# Montana register map
Vendor: ONSemiconductor; Series: Montana Series; File version: 1.0
CPU: CM33 r0p4, little endian, MPU, FPU, 3 interrupt priority bits
Registers are 32-bit, read-write, reset 0x0 unless marked. A register's access mark holds for its fields unless they carry their own. Offsets are from the block's base; [hi:lo] are bit positions; 'fields as' and 'values as' point back to an identical list.

## SYSCTRL — System Control
Base 0x40000000
0x00 SYSCTRL_CM33_LOOP_CACHE_CFG — CM33 Loop Cache Configuration
  [0] CM33_LOOP_CACHE_ENABLE
    0=CM33_LOOP_CACHE_DISABLE (CM33 loop cache disabled); 1=CM33_LOOP_CACHE_ENABLE (CM33 loop cache enabled)
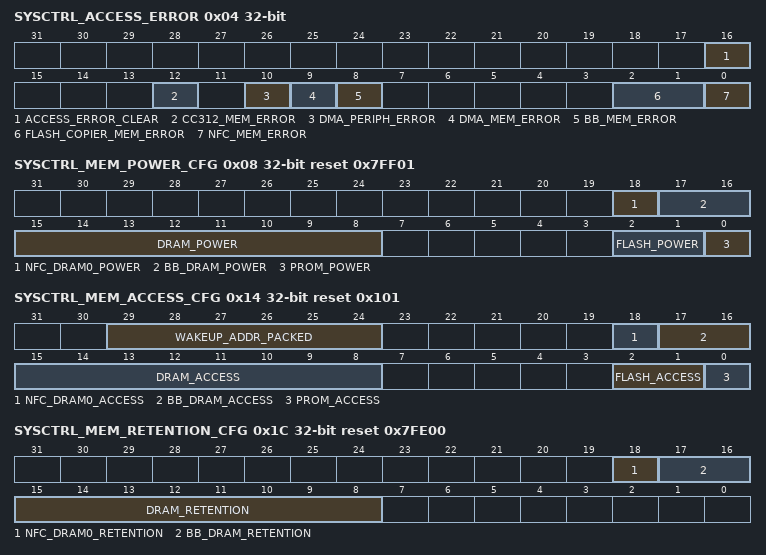
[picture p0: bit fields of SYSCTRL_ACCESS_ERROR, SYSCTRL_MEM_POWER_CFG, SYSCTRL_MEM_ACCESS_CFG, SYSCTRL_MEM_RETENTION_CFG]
0x04 SYSCTRL_ACCESS_ERROR (reset mask 0x1707) — Memory and Peripheral Access Error Flags
  [16] ACCESS_ERROR_CLEAR wo — Write a 1 to clear the access error flags
    1=SYSCTRL_ACCESS_ERROR_CLEAR (Clear the access error flags)
  [12] CC312_MEM_ERROR ro — CC312 memory error flag
    0=CC312_MEM_NO_ERROR_DETECTED (No CC312 memory error detected); 1=CC312_MEM_ERROR_DETECTED (CC312 has accessed an isolated memory)
  [10] DMA_PERIPH_ERROR ro — DMA peripheral access error flag
    0=DMA_PERIPH_NO_ERROR_DETECTED (No DMA peripheral access error detected); 1=DMA_PERIPH_ERROR_DETECTED (DMA received a peripheral access error)
  [9] DMA_MEM_ERROR ro — DMA memory error flag
    0=DMA_MEM_NO_ERROR_DETECTED (No DMA memory error detected); 1=DMA_MEM_ERROR_DETECTED (DMA has accessed an isolated memory)
  [8] BB_MEM_ERROR ro — Baseband memory error flag
    0=BB_MEM_NO_ERROR_DETECTED (No baseband memory error detected); 1=BB_MEM_ERROR_DETECTED (Baseband has accessed an isolated memory)
  [2:1] FLASH_COPIER_MEM_ERROR ro — FLASH[1:0] copier memory error flag
    0=FLASH0_COPIER_MEM_NO_ERROR_DETECTED (No FLASH copier memory error detected); 0=FLASH1_COPIER_MEM_NO_ERROR_DETECTED (No FLASH copier memory error detected); 1=FLASH0_COPIER_MEM_ERROR_DETECTED (FLASH0 or FLASH1 copier have accessed an isolated memory); 2=FLASH1_COPIER_MEM_ERROR_DETECTED (FLASH0 or FLASH1 copier have accessed an isolated memory)
  [0] NFC_MEM_ERROR ro — NFC controller memory error flag
    0=NFC_MEM_NO_ERROR_DETECTED (No NFC controller memory error detected); 1=NFC_MEM_ERROR_DETECTED (NFC controller memory error detected)
0x08 SYSCTRL_MEM_POWER_CFG reset 0x7FF01 — Memory Power Configuration
  [18] NFC_DRAM0_POWER — NFC DRAM0 power configuration
    0=NFC_DRAM0_POWER_DISABLE (NFC DRAM0 power disabled); 1=NFC_DRAM0_POWER_ENABLE (NFC DRAM0 power enabled)
  [17:16] BB_DRAM_POWER — Baseband DRAM[1:0] power configuration (one bit per RAM instance)
    0=BB_DRAM0_POWER_DISABLE (Baseband DRAM0 power disabled); 0=BB_DRAM1_POWER_DISABLE (Baseband DRAM1 power disabled); 1=BB_DRAM0_POWER_ENABLE (Baseband DRAM0 power enabled); 2=BB_DRAM1_POWER_ENABLE (Baseband DRAM1 power enabled)
  [15:8] DRAM_POWER — DRAM[7:0] power configuration (one bit per RAM instance)
    0=DRAM0_POWER_DISABLE (DRAM0 power disabled); 0=DRAM1_POWER_DISABLE (DRAM1 power disabled); 0=DRAM2_POWER_DISABLE (DRAM2 power disabled); 0=DRAM3_POWER_DISABLE (DRAM3 power disabled); 0=DRAM4_POWER_DISABLE (DRAM4 power disabled); 0=DRAM5_POWER_DISABLE (DRAM5 power disabled); 0=DRAM6_POWER_DISABLE (DRAM6 power disabled); 0=DRAM7_POWER_DISABLE (DRAM7 power disabled); 1=DRAM0_POWER_ENABLE (DRAM0 power enabled); 2=DRAM1_POWER_ENABLE (DRAM1 power enabled); 4=DRAM2_POWER_ENABLE (DRAM2 power enabled); 8=DRAM3_POWER_ENABLE (DRAM3 power enabled); 16=DRAM4_POWER_ENABLE (DRAM4 power enabled); 32=DRAM5_POWER_ENABLE (DRAM5 power enabled); 64=DRAM6_POWER_ENABLE (DRAM6 power enabled); 128=DRAM7_POWER_ENABLE (DRAM7 power enabled)
  [2:1] FLASH_POWER — Flash[1:0] power configuration (one bit per FLASH instance)
    0=FLASH0_POWER_DISABLE (FLASH0 power disabled); 0=FLASH1_POWER_DISABLE (FLASH1 power disabled); 1=FLASH0_POWER_ENABLE (FLASH0 power enabled); 2=FLASH1_POWER_ENABLE (FLASH1 power enabled)
  [0] PROM_POWER — PROM power configuration
    0=PROM_POWER_DISABLE (PROM power disabled); 1=PROM_POWER_ENABLE (PROM power enabled)
0x14 SYSCTRL_MEM_ACCESS_CFG reset 0x101 — Memory Access Configuration and Wakeup Restore Address in packed 4-bit format
  [29:24] WAKEUP_ADDR_PACKED — Wakeup restore address in packed 6-bit format. When written, SYSCTRL_WAKEUP_ADDR is updated. This field reads back as zero when SYSCTRL_WAKEUP_ADDR does not point to an enabled RAM instance.
  [18] NFC_DRAM0_ACCESS — NFC DRAM0 access configuration
    0=NFC_DRAM0_ACCESS_DISABLE (NFC DRAM0 access disabled); 1=NFC_DRAM0_ACCESS_ENABLE (NFC RAM0 access enabled)
  [17:16] BB_DRAM_ACCESS — Baseband DRAM[1:0] access configuration
    0=BB_DRAM0_ACCESS_DISABLE (Baseband DRAM0 access disabled); 0=BB_DRAM1_ACCESS_DISABLE (Baseband DRAM1 access disabled); 1=BB_DRAM0_ACCESS_ENABLE (Baseband DRAM0 access enabled); 2=BB_DRAM1_ACCESS_ENABLE (Baseband DRAM1 access enabled)
  [15:8] DRAM_ACCESS — DRAM[7:0] access configuration
    0=DRAM0_ACCESS_DISABLE (DRAM0 access disabled); 0=DRAM1_ACCESS_DISABLE (DRAM1 access disabled); 0=DRAM2_ACCESS_DISABLE (DRAM2 access disabled); 0=DRAM3_ACCESS_DISABLE (DRAM3 access disabled); 0=DRAM4_ACCESS_DISABLE (DRAM4 access disabled); 0=DRAM5_ACCESS_DISABLE (DRAM5 access disabled); 0=DRAM6_ACCESS_DISABLE (DRAM6 access disabled); 0=DRAM7_ACCESS_DISABLE (DRAM7 access disabled); 1=DRAM0_ACCESS_ENABLE (DRAM0 access enabled); 2=DRAM1_ACCESS_ENABLE (DRAM1 access enabled); 4=DRAM2_ACCESS_ENABLE (DRAM2 access enabled); 8=DRAM3_ACCESS_ENABLE (DRAM3 access enabled); 16=DRAM4_ACCESS_ENABLE (DRAM4 access enabled); 32=DRAM5_ACCESS_ENABLE (DRAM5 access enabled); 64=DRAM6_ACCESS_ENABLE (DRAM6 access enabled); 128=DRAM7_ACCESS_ENABLE (DRAM7 access enabled)
  [2:1] FLASH_ACCESS — FLASH[1:0] access configuration
    0=FLASH0_ACCESS_DISABLE (FLASH0 access disabled); 0=FLASH1_ACCESS_DISABLE (FLASH1 access disabled); 1=FLASH0_ACCESS_ENABLE (FLASH0 access enabled); 2=FLASH1_ACCESS_ENABLE (FLASH1 access enabled)
  [0] PROM_ACCESS — PROM access configuration
    0=PROM_ACCESS_DISABLE (PROM access disabled); 1=PROM_ACCESS_ENABLE (PROM access enabled)
0x18 SYSCTRL_WAKEUP_ADDR — Wakeup Restore Address in Unpacked 32-bit Format
  [31:0] WAKEUP_ADDR — Wakeup restore address in unpacked 32-bit format.
0x1C SYSCTRL_MEM_RETENTION_CFG reset 0x7FE00 — Memory Retention Configuration
  [18] NFC_DRAM0_RETENTION — NFC DRAM0 retention configuration
    0=NFC_DRAM0_NORMAL_MODE; 1=NFC_DRAM0_RETENTION_MODE
  [17:16] BB_DRAM_RETENTION — Baseband DRAM[1:0] retention configuration
    0=BB_DRAM0_NORMAL_MODE (Baseband DRAM0 normal mode); 0=BB_DRAM1_NORMAL_MODE (Baseband DRAM1 normal mode); 1=BB_DRAM0_RETENTION_MODE (Baseband DRAM0 retention mode); 2=BB_DRAM1_RETENTION_MODE (Baseband DRAM1 retention mode)
  [15:8] DRAM_RETENTION — DRAM[7:0] retention configuration
    0=DRAM0_NORMAL_MODE; 0=DRAM1_NORMAL_MODE; 0=DRAM2_NORMAL_MODE; 0=DRAM3_NORMAL_MODE; 0=DRAM4_NORMAL_MODE; 0=DRAM5_NORMAL_MODE; 0=DRAM6_NORMAL_MODE; 0=DRAM7_NORMAL_MODE; 1=DRAM0_RETENTION_MODE; 2=DRAM1_RETENTION_MODE; 4=DRAM2_RETENTION_MODE; 8=DRAM3_RETENTION_MODE; 16=DRAM4_RETENTION_MODE; 32=DRAM5_RETENTION_MODE; 64=DRAM6_RETENTION_MODE; 128=DRAM7_RETENTION_MODE
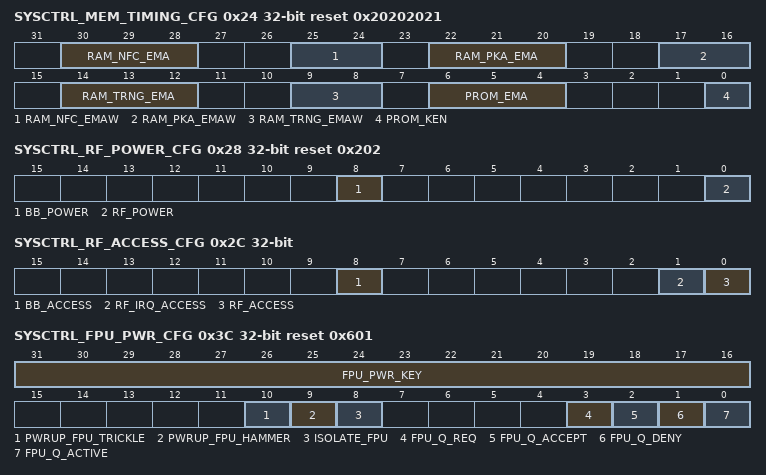
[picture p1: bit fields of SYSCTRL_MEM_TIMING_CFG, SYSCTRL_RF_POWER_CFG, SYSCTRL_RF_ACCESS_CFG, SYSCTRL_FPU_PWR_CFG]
0x24 SYSCTRL_MEM_TIMING_CFG reset 0x20202021 — Memory Timing Configuration
  [30:28] RAM_NFC_EMA — RAM extra margin configuration for NFC RAM
    0=RAM_NFC_EMA_MIN (RAM minimum extra margin); 2=RAM_NFC_EMA_DEFAULT (RAM default extra margin); 7=RAM_NFC_EMA_MAX (RAM maximum extra margin)
  [25:24] RAM_NFC_EMAW — RAM write extra margin configuration for NFC RAM
    0=RAM_NFC_EMAW_DEFAULT (RAM default/minimum extra write margin); 3=RAM_NFC_EMAW_MAX (RAM maximum extra write margin)
  [22:20] RAM_PKA_EMA — RAM extra margin configuration for PKA RAM
    0=RAM_PKA_EMA_MIN (RAM minimum extra margin); 2=RAM_PKA_EMA_DEFAULT (RAM default extra margin); 7=RAM_PKA_EMA_MAX (RAM maximum extra margin)
  [17:16] RAM_PKA_EMAW — RAM write extra margin configuration for PKA RAM
    0=RAM_PKA_EMAW_DEFAULT (RAM default/minimum extra write margin); 3=RAM_PKA_EMAW_MAX (RAM maximum extra write margin)
  [14:12] RAM_TRNG_EMA — RAM extra margin configuration for TRNG RAM
    0=RAM_TRNG_EMA_MIN (RAM minimum extra margin); 2=RAM_TRNG_EMA_DEFAULT (RAM default extra margin); 7=RAM_TRNG_EMA_MAX (RAM maximum extra margin)
  [9:8] RAM_TRNG_EMAW — RAM write extra margin configuration for TRNG RAM
    0=RAM_TRNG_EMAW_DEFAULT (RAM default/minimum extra write margin); 3=RAM_TRNG_EMAW_MAX (RAM maximum extra write margin)
  [6:4] PROM_EMA — PROM extra margin configuration
    0=PROM_EMA_MIN (PROM minimum extra margin); 2=PROM_EMA_DEFAULT (PROM default extra margin); 7=PROM_EMA_MAX (PROM maximum extra margin)
  [0] PROM_KEN — PROM bit lines keeper configuration
    0=PROM_KEN_ENABLED (PROM bit lines keeper enabled); 1=PROM_KEN_DISABLED (PROM bit lines keeper disabled)
0x28 SYSCTRL_RF_POWER_CFG reset 0x202 — RF Power Configuration
  [8] BB_POWER — Base Band power configuration
    0=BB_POWER_DISABLE (Base Band power disabled); 1=BB_POWER_ENABLE (Base Band power enabled)
  [0] RF_POWER — RF power configuration
    0=RF_POWER_DISABLE (RF power disabled); 1=RF_POWER_ENABLE (RF power enabled)
0x2C SYSCTRL_RF_ACCESS_CFG — RF Access Configuration
  [8] BB_ACCESS — Base Band access
    0=BB_ACCESS_DISABLE (BB access disabled); 1=BB_ACCESS_ENABLE (BB access enabled)
  [1] RF_IRQ_ACCESS — RF IRQ access configuration
    0=RF_IRQ_ACCESS_DISABLE (RF IRQ access disabled); 1=RF_IRQ_ACCESS_ENABLE (RF IRQ access enabled)
  [0] RF_ACCESS — RF access configuration
    0=RF_ACCESS_DISABLE (RF access disabled); 1=RF_ACCESS_ENABLE (RF access enabled)
0x34 SYSCTRL_WAKEUP_PAD ro — WAKEUP Pad Value
  [0] WAKEUP_PAD_VALUE
    0=WAKEUP_PAD_LOW (WAKEUP pad value equal to '0'); 1=WAKEUP_PAD_HIGH (WAKEUP pad value equal to '1')
0x3C SYSCTRL_FPU_PWR_CFG reset 0x601 (reset mask 0x170F) — FPU Power Configuration
  [31:16] FPU_PWR_KEY wo — Key to enable write to this register
    0x4644=FPU_WRITE_KEY (Key to enable write to this register)
  [10] PWRUP_FPU_TRICKLE — Power control for FPU primary current in-rush limited supply
    0=FPU_PWR_TRICKLE_DISABLE (FPU power trickle disabled); 1=FPU_PWR_TRICKLE_ENABLE (FPU power trickle enabled)
  [9] PWRUP_FPU_HAMMER — Power control for FPU primary low impedance supply
    0=FPU_PWR_HAMMER_DISABLE (FPU power hammer disabled); 1=FPU_PWR_HAMMER_ENABLE (FPU power hammer enabled)
  [8] ISOLATE_FPU — Isolation control for FPU
    0=FPU_NOT_ISOLATE (FPU accessible); 1=FPU_ISOLATE (FPU isolated)
  [3] FPU_Q_REQ — FPU domain quiescence request signal
    0=FPU_Q_NOT_REQUEST (FPU quiescence not requested); 1=FPU_Q_REQUEST (FPU quiescence requested)
  [2] FPU_Q_ACCEPT ro — FPU domain quiescence request accepted
    0=FPU_Q_NOT_ACCEPTED (FPU quiescence not accepted); 1=FPU_Q_ACCEPTED (FPU quiescence accepted)
  [1] FPU_Q_DENY ro — FPU domain quiescence request denied
    0=FPU_Q_NOT_DENIED (FPU quiescence not denied); 1=FPU_Q_DENIED (FPU quiescence denied)
  [0] FPU_Q_ACTIVE ro — FPU logic active or activation request
    0=FPU_Q_INACTIVE (FPU inactive); 1=FPU_Q_ACTIVE (FPU active)
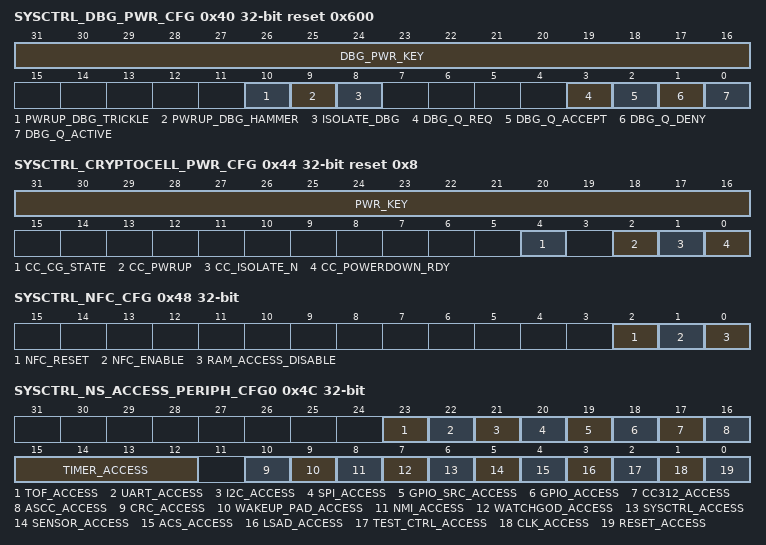
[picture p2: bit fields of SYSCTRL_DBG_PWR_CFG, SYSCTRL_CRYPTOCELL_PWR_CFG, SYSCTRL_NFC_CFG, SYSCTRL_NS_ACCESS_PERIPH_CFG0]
0x40 SYSCTRL_DBG_PWR_CFG reset 0x600 (reset mask 0x170F) — DEBUG Power Configuration
  [31:16] DBG_PWR_KEY wo — Key to enable write to this register
    0x5755=DBG_WRITE_KEY (Key to enable write to this register)
  [10] PWRUP_DBG_TRICKLE — Power control for Debug primary current in-rush limited supply
    0=DBG_PWR_TRICKLE_DISABLE (DBG power trickle disabled); 1=DBG_PWR_TRICKLE_ENABLE (DBG power trickle enabled)
  [9] PWRUP_DBG_HAMMER — Power control for Debug primary low impedance supply
    0=DBG_PWR_HAMMER_DISABLE (DBG power hammer disabled); 1=DBG_PWR_HAMMER_ENABLE (DBG power hammer enabled)
  [8] ISOLATE_DBG — Isolation control for Debug
    0=DBG_NOT_ISOLATE (DBG accessible); 1=DBG_ISOLATE (DBG isolated)
  [3] DBG_Q_REQ — Debug domain quiescence request signal
    0=DBG_Q_NOT_REQUEST (DBG quiescence not requested); 1=DBG_Q_REQUEST (DBG quiescence requested)
  [2] DBG_Q_ACCEPT ro — Debug domain quiescence request accepted
    0=DBG_Q_NOT_ACCEPTED (DBG quiescence not accepted); 1=DBG_Q_ACCEPTED (DBG quiescence accepted)
  [1] DBG_Q_DENY ro — Debug domain quiescence request denied
    0=DBG_Q_NOT_DENIED (DBG quiescence not denied); 1=DBG_Q_DENIED (DBG quiescence denied)
  [0] DBG_Q_ACTIVE ro — Debug logic active or activation request
    0=DBG_Q_INACTIVE (DBG inactive); 1=DBG_Q_ACTIVE (DBG active)
0x44 SYSCTRL_CRYPTOCELL_PWR_CFG reset 0x8 (reset mask 0x1F) — CryptoCell Power Configuration
  [31:16] PWR_KEY wo — Key to enable write to this register
    0x4363=CC_WRITE_KEY (Key to enable write to this register)
  [4] CC_CG_STATE ro — CryptoCell central clock gating state
    0=CC_CG_IS_IDLE (The CryptoCell is not receiving any clock); 1=CC_CG_IS_ACTIVE (The CryptoCell is receiving clock)
  [2] CC_PWRUP — Power control for CryptoCell
    0=CC_POWER_DISABLE (CryptoCell shut-down); 1=CC_POWER_ENABLE (CryptoCell powered)
  [1] CC_ISOLATE_N — CryptoCell isolate control signal
    0=CC_ISOLATE (CryptoCell isolated); 1=CC_NOT_ISOLATE (CryptoCell accessible)
  [0] CC_POWERDOWN_RDY ro — Indicates that CryptoCell can be powered down
    0=CC_PWR_DOWN_NOT_RDY (CryptoCell could not be shut-down); 1=CC_PWR_DOWN_RDY (CryptoCell can be shut-down)
0x48 SYSCTRL_NFC_CFG (reset mask 0x3) — NFC Configuration
  [2] NFC_RESET wo — Reset the NFC IP
    0=NFC_RESET_DIS (NFC reset is disable); 1=NFC_RESET_EN (NFC reset is enable)
  [1] NFC_ENABLE — Enable the NFC IP
    0=NFC_DIS (NFC is disable); 1=NFC_EN (NFC is enable)
  [0] RAM_ACCESS_DISABLE — Disable the access of the NFC to the NFC_DRAM. Overdrive the arbiter
    0=NFC_CAN_ACCESS_DRAM; 1=NFC_CANNOT_ACCESS_DRAM
0x4C SYSCTRL_NS_ACCESS_PERIPH_CFG0 — Non-Secure code access peripherals configuration
  [23] TOF_ACCESS — Allow Non-Secure code to access the TOF
    0=NS_CANNOT_ACCESS_TOF (Non-Secure code cannot access the TOF); 1=NS_CAN_ACCESS_TOF (Non-Secure code can access the TOF)
  [22] UART_ACCESS — Allow Non-Secure code to access the UART[0:0]
    0=NS_CANNOT_ACCESS_UART0 (Non-Secure code cannot access the UART0); 1=NS_CAN_ACCESS_UART0 (Non-Secure code can access the UART0)
  [21] I2C_ACCESS — Allow Non-Secure code to access the I2C[0:0]
    0=NS_CANNOT_ACCESS_I2C0 (Non-Secure code cannot access the I2C0); 1=NS_CAN_ACCESS_I2C0 (Non-Secure code can access the I2C0)
  [20] SPI_ACCESS — Allow Non-Secure code to access the SPI[0:0]
    0=NS_CANNOT_ACCESS_SPI0 (Non-Secure code cannot access the SPI0); 1=NS_CAN_ACCESS_SPI0 (Non-Secure code can access the SPI0)
  [19] GPIO_SRC_ACCESS — Allow Non-Secure code to access the GPIO_SRC
    0=NS_CANNOT_ACCESS_GPIO_SRC (Non-Secure code cannot access the GPIO_SRC); 1=NS_CAN_ACCESS_GPIO_SRC (Non-Secure code can access the GPIO_SRC)
  [18] GPIO_ACCESS — Allow Non-Secure code to access the GPIO
    0=NS_CANNOT_ACCESS_GPIO (Non-Secure code cannot access the GPIO); 1=NS_CAN_ACCESS_GPIO (Non-Secure code can access the GPIO)
  [17] CC312_ACCESS — Allow Non-Secure code to access the CC312
    0=NS_CANNOT_ACCESS_CC312 (Non-Secure code cannot access the CC312); 1=NS_CAN_ACCESS_CC312 (Non-Secure code can access the CC312)
  [16] ASCC_ACCESS — Allow Non-Secure code to access the ASCC
    0=NS_CANNOT_ACCESS_ASCC (Non-Secure code cannot access the ASCC); 1=NS_CAN_ACCESS_ASCC (Non-Secure code can access the ASCC)
  [15:12] TIMER_ACCESS — Allow Non-Secure code to access the Timer[3:0]
    0=NS_CANNOT_ACCESS_TIMER0 (Non-Secure code cannot access the Timer0); 0=NS_CANNOT_ACCESS_TIMER1 (Non-Secure code cannot access the Timer1); 0=NS_CANNOT_ACCESS_TIMER2 (Non-Secure code cannot access the Timer2); 0=NS_CANNOT_ACCESS_TIMER3 (Non-Secure code cannot access the Timer3); 1=NS_CAN_ACCESS_TIMER0 (Non-Secure code can access the Timer0); 2=NS_CAN_ACCESS_TIMER1 (Non-Secure code can access the Timer1); 4=NS_CAN_ACCESS_TIMER2 (Non-Secure code can access the Timer2); 8=NS_CAN_ACCESS_TIMER3 (Non-Secure code can access the Timer3)
  [10] CRC_ACCESS — Allow Non-Secure code to access the CRC
    0=NS_CANNOT_ACCESS_CRC (Non-Secure code cannot access the CRC); 1=NS_CAN_ACCESS_CRC (Non-Secure code can access the CRC)
  [9] WAKEUP_PAD_ACCESS — Allow Non-Secure code to access the WAKEUP_PAD
    0=NS_CANNOT_ACCESS_WAKEUP_PAD (Non-Secure code cannot access the WAKEUP_PAD); 1=NS_CAN_ACCESS_WAKEUP_PAD (Non-Secure code can access the WAKEUP_PAD)
  [8] NMI_ACCESS — Allow Non-Secure code to access the NMI
    0=NS_CANNOT_ACCESS_NMI (Non-Secure code cannot access the NMI); 1=NS_CAN_ACCESS_NMI (Non-Secure code can access the NMI)
  [7] WATCHGOD_ACCESS — Allow Non-Secure code to access the Watchdog
    0=NS_CANNOT_ACCESS_WATCHDOG (Non-Secure code cannot access the Watchdog); 1=NS_CAN_ACCESS_WATCHDOG (Non-Secure code can access the Watchdog)
  [6] SYSCTRL_ACCESS — Allow Non-Secure code to access the SYSCTRL
    0=NS_CANNOT_ACCESS_SYSCTRL (Non-Secure code cannot access the SYSCTRL); 1=NS_CAN_ACCESS_SYSCTRL (Non-Secure code can access the SYSCTRL)
  [5] SENSOR_ACCESS — Allow Non-Secure code to access the Sensor
    0=NS_CANNOT_ACCESS_SENSOR (Non-Secure code cannot access the Sensor); 1=NS_CAN_ACCESS_SENSOR (Non-Secure code can access the Sensor)
  [4] ACS_ACCESS — Allow Non-Secure code to access the ACS
    0=NS_CANNOT_ACCESS_ACS (Non-Secure code cannot access the ACS); 1=NS_CAN_ACCESS_ACS (Non-Secure code can access the ACS)
  [3] LSAD_ACCESS — Allow Non-Secure code to access the LSAD config
    0=NS_CANNOT_ACCESS_LSAD (Non-Secure code cannot access the LSAD); 1=NS_CAN_ACCESS_LSAD (Non-Secure code can access the LSAD)
  [2] TEST_CTRL_ACCESS — Allow Non-Secure code to access the TEST_CTRL config
    0=NS_CANNOT_ACCESS_TEST_CTRL (Non-Secure code cannot access the TEST_CTRL); 1=NS_CAN_ACCESS_TEST_CTRL (Non-Secure code can access the TEST_CTRL)
  [1] CLK_ACCESS — Allow Non-Secure code to access the CLK config
    0=NS_CANNOT_ACCESS_CLK (Non-Secure code cannot access the CLK config); 1=NS_CAN_ACCESS_CLK (Non-Secure code can access the CLK config)
  [0] RESET_ACCESS — Allow Non-Secure code to access the Reset
    0=NS_CANNOT_ACCESS_RESET (Non-Secure code cannot access the Reset); 1=NS_CAN_ACCESS_RESET (Non-Secure code can access the Reset)
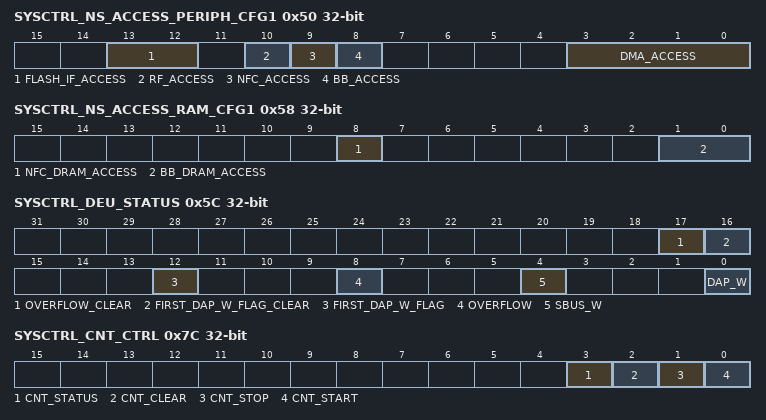
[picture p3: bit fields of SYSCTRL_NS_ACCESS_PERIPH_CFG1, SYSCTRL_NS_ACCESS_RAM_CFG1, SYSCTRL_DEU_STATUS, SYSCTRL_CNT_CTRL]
0x50 SYSCTRL_NS_ACCESS_PERIPH_CFG1 — Non-Secure code access peripherals configuration
  [13:12] FLASH_IF_ACCESS — Allow Non-Secure code to access the FLASH_IF[1:0]
    0=NS_CANNOT_ACCESS_FLASH_IF0 (Non-Secure code cannot access the FLASH_IF0); 0=NS_CANNOT_ACCESS_FLASH_IF1 (Non-Secure code cannot access the FLASH_IF1); 1=NS_CAN_ACCESS_FLASH_IF0 (Non-Secure code can access the FLASH_IF0); 2=NS_CAN_ACCESS_FLASH_IF1 (Non-Secure code can access the FLASH_IF1)
  [10] RF_ACCESS — Allow Non-Secure code to access the RF
    0=NS_CANNOT_ACCESS_RF (Non-Secure code cannot access the RF); 1=NS_CAN_ACCESS_RF (Non-Secure code can access the RF)
  [9] NFC_ACCESS — Allow Non-Secure code to access the NFC
    0=NS_CANNOT_ACCESS_NFC (Non-Secure code cannot access the NFC); 1=NS_CAN_ACCESS_NFC (Non-Secure code can access the NFC)
  [8] BB_ACCESS — Allow Non-Secure code to access the BB
    0=NS_CANNOT_ACCESS_BB (Non-Secure code cannot access the BB); 1=NS_CAN_ACCESS_BB (Non-Secure code can access the BB)
  [3:0] DMA_ACCESS — Allow Non-Secure code to access the DMA[3:0]
    0=NS_CANNOT_ACCESS_DMA0 (Non-Secure code cannot access the DMA0); 0=NS_CANNOT_ACCESS_DMA1 (Non-Secure code cannot access the DMA1); 0=NS_CANNOT_ACCESS_DMA2 (Non-Secure code cannot access the DMA2); 0=NS_CANNOT_ACCESS_DMA3 (Non-Secure code cannot access the DMA3); 1=NS_CAN_ACCESS_DMA0 (Non-Secure code can access the DMA0); 2=NS_CAN_ACCESS_DMA1 (Non-Secure code can access the DMA1); 4=NS_CAN_ACCESS_DMA2 (Non-Secure code can access the DMA2); 8=NS_CAN_ACCESS_DMA3 (Non-Secure code can access the DMA3)
0x54 SYSCTRL_NS_ACCESS_RAM_CFG0 — Non-Secure code access RAM configuration
  [7:0] DRAM_ACCESS — Allow Non-Secure to access DRAM[7:0]
    0=NS_CANNOT_ACCESS_DRAM0 (Non-Secure code cannot access the DRAM0); 0=NS_CANNOT_ACCESS_DRAM1 (Non-Secure code cannot access the DRAM1); 0=NS_CANNOT_ACCESS_DRAM2 (Non-Secure code cannot access the DRAM2); 0=NS_CANNOT_ACCESS_DRAM3 (Non-Secure code cannot access the DRAM3); 0=NS_CANNOT_ACCESS_DRAM4 (Non-Secure code cannot access the DRAM4); 0=NS_CANNOT_ACCESS_DRAM5 (Non-Secure code cannot access the DRAM5); 0=NS_CANNOT_ACCESS_DRAM6 (Non-Secure code cannot access the DRAM6); 0=NS_CANNOT_ACCESS_DRAM7 (Non-Secure code cannot access the DRAM7); 1=NS_CAN_ACCESS_DRAM0 (Non-Secure code can access the DRAM0); 2=NS_CAN_ACCESS_DRAM1 (Non-Secure code can access the DRAM1); 4=NS_CAN_ACCESS_DRAM2 (Non-Secure code can access the DRAM2); 8=NS_CAN_ACCESS_DRAM3 (Non-Secure code can access the DRAM3); 16=NS_CAN_ACCESS_DRAM4 (Non-Secure code can access the DRAM4); 32=NS_CAN_ACCESS_DRAM5 (Non-Secure code can access the DRAM5); 64=NS_CAN_ACCESS_DRAM6 (Non-Secure code can access the DRAM6); 128=NS_CAN_ACCESS_DRAM7 (Non-Secure code can access the DRAM7)
0x58 SYSCTRL_NS_ACCESS_RAM_CFG1 — Non-Secure code access RAM configuration
  [8] NFC_DRAM_ACCESS — Allow Non-Secure code to access NFC_DRAM
    0=NS_CANNOT_ACCESS_NFC_DRAM (Non-Secure code cannot access the NFC_DRAM); 1=NS_CAN_ACCESS_NFC_DRAM (Non-Secure code can access the NFC_DRAM)
  [1:0] BB_DRAM_ACCESS — Allow Non-Secure code to access BB_DRAM[1:0]
    0=NS_CANNOT_ACCESS_BB_DRAM0 (Non-Secure code cannot access the BB_DRAM0); 0=NS_CANNOT_ACCESS_BB_DRAM1 (Non-Secure code cannot access the BB_DRAM1); 1=NS_CAN_ACCESS_BB_DRAM0 (Non-Secure code can access the BB_DRAM0); 2=NS_CAN_ACCESS_BB_DRAM1 (Non-Secure code can access the BB_DRAM1)
0x5C SYSCTRL_DEU_STATUS (reset mask 0x1111) — Data Exchange Unit Status
  [17] OVERFLOW_CLEAR wo — Clear OVERFLOW flag
    1=DEU_OVERFLOW_CLEAR (Clear the flag OVERFLOW)
  [16] FIRST_DAP_W_FLAG_CLEAR wo — Clear the FIRST_DAP_W_FLAG
    1=DEU_FIRST_DAP_W_FLAG_CLEAR (Clear the flag FIRST_DAP_W_FLAG)
  [12] FIRST_DAP_W_FLAG ro — First Debug access port write flag
    0=FIRST_DAP_W_FLAG_LOW (First DAP write flag low); 1=FIRST_DAP_W_FLAG_HIGH (First DAP write flag high)
  [8] OVERFLOW ro — High when DEU_DATA register is written before been read by any bus. Clear via CLR_OVERFLOW action bit.
    0=NO_OVERFLOW (No overflow on DEU_DATA register); 1=OVERFLOW (Overflow on DEU_DATA register)
  [4] SBUS_W ro — Set when SBus writes the DEU_DATA, clear when the debug access port read the DEU_DATA register
    0=DAP_R_DATA (Debug access port has read the DEU_DATA register.); 1=SBUS_W_DATA (SBus has written DEU_DATA register.)
  [0] DAP_W ro — Set when the debug access port writes the DEU_DATA, clear when the SBus reads the DEU_DATA register.
    0=SBUS_R_DATA (SBus has read the DEU_DATA register.); 1=DAP_W_DATA (Debug access port has written DEU_DATA register.)
0x60 SYSCTRL_DEU_DATA — Data Exchange Unit Data
  [31:0] DEU_DATA — Data exchange unit data
0x64 SYSCTRL_PROD_STATUS reset not defined — Production Test Status
  [31:0] PROD_STATUS wo — Production Status
    0x5072446F=PROD_DONE (Indicate the production test is done.)
0x7C SYSCTRL_CNT_CTRL (reset mask 0x8) — Activity Counters Control
  [3] CNT_STATUS ro — Activity counters status bit
    0=CNT_STOPPED (Activity counters stopped); 1=CNT_RUNNING (Activity counters running)
  [2] CNT_CLEAR wo — Clear activity counters
    1=CNT_CLEAR (Clear activity counters)
  [1] CNT_STOP wo — Stop activity counters
    1=CNT_STOP (Stop activity counters)
  [0] CNT_START wo — Start activity counters
    1=CNT_START (Start activity counters)
0x80 SYSCTRL_SYSCLK_CNT — System Clock Counter Value
  [31:0] SYSCLK_CNT — System clock counter value
0x84 SYSCTRL_CM33_CNT — CM33 Activity Counter Value
  [31:0] CM33_CNT — CM33 activity counter value
0x88 SYSCTRL_CBUS_CNT — CBus Activity Counter Value
  [31:0] CBUS_CNT — CBus-instruction activity counter value
0x8C SYSCTRL_FLASH_READ_CNT — Flash Read Access Counter Value
  [31:0] FLASH_READ_CNT — Flash read access counter value
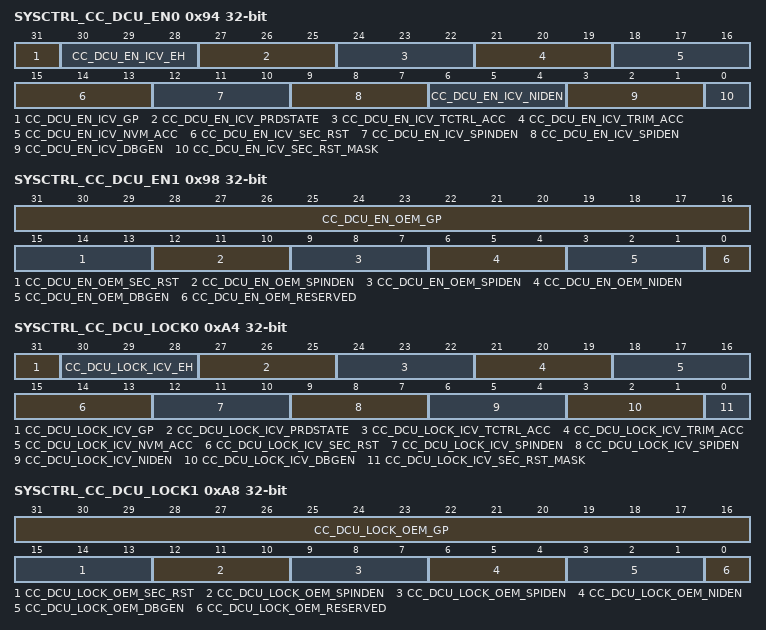
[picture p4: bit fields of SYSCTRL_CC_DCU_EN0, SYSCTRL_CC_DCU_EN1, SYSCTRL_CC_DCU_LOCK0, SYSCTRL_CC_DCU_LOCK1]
0x94 SYSCTRL_CC_DCU_EN0 ro — CryptoCell Always On block ICV owned DCU_EN [31:0] state
  [31] CC_DCU_EN_ICV_GP — Always On ICV governed dcu_en0 general purpose bits
  [30:28] CC_DCU_EN_ICV_EH — Always On ICV governed energy harversting signature. Majority of the bis must be set to confirm the state.
  [27:25] CC_DCU_EN_ICV_PRDSTATE — Always On ICV governed production state identifier
  [24:22] CC_DCU_EN_ICV_TCTRL_ACC — Always On ICV governed test control configuration access control. Majority of the bits must be set to enable the feature
  [21:19] CC_DCU_EN_ICV_TRIM_ACC — Always On ICV governed MNVR and chip trim access control. Majority of the bits must be set to enable the feature
  [18:16] CC_DCU_EN_ICV_NVM_ACC — Always On ICV governed NVM access control. Majority of the bits must be set to enable the feature
  [15:13] CC_DCU_EN_ICV_SEC_RST — Always On ICV governed secure reset enable. If any of these bits are set and the part is in SE state, the cc312_top is reset
  [12:10] CC_DCU_EN_ICV_SPINDEN — Always On ICV governed CM33 secure non-intrusive debug enable control. Majority of the bits must be set to enable the feature
  [9:7] CC_DCU_EN_ICV_SPIDEN — Always On ICV governed CM33 secure intrusive debug enable control. Majority of the bits must be set to enable the feature
  [6:4] CC_DCU_EN_ICV_NIDEN — Always On ICV governed CM33 non-intrusive debug enable control. Majority of the bits must be set to enable the feature
  [3:1] CC_DCU_EN_ICV_DBGEN — Always On ICV governed CM33 debug enable control. Majority of the bits must be set to enable the feature
  [0] CC_DCU_EN_ICV_SEC_RST_MASK — Always On ICV governed secure reset mask used in FW
    0=CC_SECURE_RST_FW_EN (The FW does not mask the secure debug reset bits); 1=CC_SECURE_RST_FW_DIS (The FW masks the secure debug reset bits, no reset can be issued)
0x98 SYSCTRL_CC_DCU_EN1 ro — CryptoCell Always On block OEM owned DCU_EN [63:32] state
  [31:16] CC_DCU_EN_OEM_GP — Always On OEM governed dcu_en1 general purpose bits
  [15:13] CC_DCU_EN_OEM_SEC_RST — Always On OEM governed secure reset enable. If any of these bits are set and the part is in SE state, the cc312_top is reset
  [12:10] CC_DCU_EN_OEM_SPINDEN — Always On OEM governed CM33 secure non-intrusive debug enable control. Majority of the bits must be set to enable the feature
  [9:7] CC_DCU_EN_OEM_SPIDEN — Always On OEM governed CM33 secure intrusive debug enable control. Majority of the bits must be set to enable the feature
  [6:4] CC_DCU_EN_OEM_NIDEN — Always On OEM governed CM33 non-intrusive debug enable control. Majority of the bits must be set to enable the feature
  [3:1] CC_DCU_EN_OEM_DBGEN — Always On OEM governed CM33 debug enable control. Majority of the bits must be set to enable the feature
  [0] CC_DCU_EN_OEM_RESERVED — Always On OEM allocated reserved bit (unused)
0x9C SYSCTRL_CC_DCU_EN2 ro — CryptoCell Always On block ICV owned DCU_EN [95:64] state
  [31:0] CC_DCU_EN2 — Always On block DCU_EN2 state
0xA0 SYSCTRL_CC_DCU_EN3 ro — CryptoCell Always On block OEM owned DCU_EN [127:96] state
  [31:0] CC_DCU_EN3 — Always On block DCU_EN3 state
0xA4 SYSCTRL_CC_DCU_LOCK0 ro — CryptoCell Always On block ICV owned DCU_LOCK [31:0] state
  [31] CC_DCU_LOCK_ICV_GP — Always On dcu_en0 general purpose bits lock. All bits must be locked to assure that the state is locked
  [30:28] CC_DCU_LOCK_ICV_EH — Always On energy harvesting signature lock. All bits must be locked to assure that the state is locked
  [27:25] CC_DCU_LOCK_ICV_PRDSTATE — Always On production state identifier lock. All bits must be locked to assure that the state is locked
  [24:22] CC_DCU_LOCK_ICV_TCTRL_ACC — Always On test control configuration access control lock. All bits must be locked to assure that the state is locked
  [21:19] CC_DCU_LOCK_ICV_TRIM_ACC — Always On MNVR and chip trim access control lock. All bits must be locked to assure that the state is locked
  [18:16] CC_DCU_LOCK_ICV_NVM_ACC — Always On NVM access control lock. All bits must be locked to assure that the state is locked
  [15:13] CC_DCU_LOCK_ICV_SEC_RST — Always On ICV secure reset enable lock. All bits must be locked to assure that the state is locked
  [12:10] CC_DCU_LOCK_ICV_SPINDEN — Always On ICV CM33 secure non-intrusive debug enable control lock. All bits must be locked to assure that the state is locked
  [9:7] CC_DCU_LOCK_ICV_SPIDEN — Always On ICV CM33 secure intrusive debug enable control lock. All bits must be locked to assure that the state is locked
  [6:4] CC_DCU_LOCK_ICV_NIDEN — Always On ICV CM33 non-intrusive debug enable control lock. All bits must be locked to assure that the state is locked
  [3:1] CC_DCU_LOCK_ICV_DBGEN — Always On ICV CM33 debug enable control lock. All bits must be locked to assure that the state is locked
  [0] CC_DCU_LOCK_ICV_SEC_RST_MASK — Always On ICV secure reset mask lock
    0=CC_SECURE_RST_MASK_UNLOCKED (The FW does not lock the secure debug reset mask bit); 1=CC_SECURE_RST_MASK_LOCKED (The FW locks the secure debug reset mask bit)
0xA8 SYSCTRL_CC_DCU_LOCK1 ro — CryptoCell Always On block OEM owned DCU_LOCK [63:32] state
  [31:16] CC_DCU_LOCK_OEM_GP — Always On OEM governed dcu_en1 general purpose bits lock
  [15:13] CC_DCU_LOCK_OEM_SEC_RST — Always On OEM governed secure reset lock. All bits must be locked to assure that the state is locked
  [12:10] CC_DCU_LOCK_OEM_SPINDEN — Always On OEM governed CM33 secure non-intrusive debug enable control lock. All bits must be locked to assure that the state is locked
  [9:7] CC_DCU_LOCK_OEM_SPIDEN — Always On OEM governed CM33 secure intrusive debug enable control lock. All bits must be locked to assure that the state is locked
  [6:4] CC_DCU_LOCK_OEM_NIDEN — Always On OEM governed CM33 non-intrusive debug enable control lock. All bits must be locked to assure that the state is locked
  [3:1] CC_DCU_LOCK_OEM_DBGEN — Always On OEM governed CM33 debug enable control lock. All bits must be locked to assure that the state is locked
  [0] CC_DCU_LOCK_OEM_RESERVED — Always On OEM allocated reserved bit (unused)
0xAC SYSCTRL_CC_DCU_LOCK2 ro — CryptoCell Always On block ICV owned DCU_LOCK [95:64] state
  [31:0] CC_DCU_LOCK2 — Always On block DCU_LOCK2 state
0xB0 SYSCTRL_CC_DCU_LOCK3 ro — CryptoCell Always On block OEM owned DCU_LOCK [127:96] state
  [31:0] CC_DCU_LOCK3 — Always On block DCU_LOCK3 state
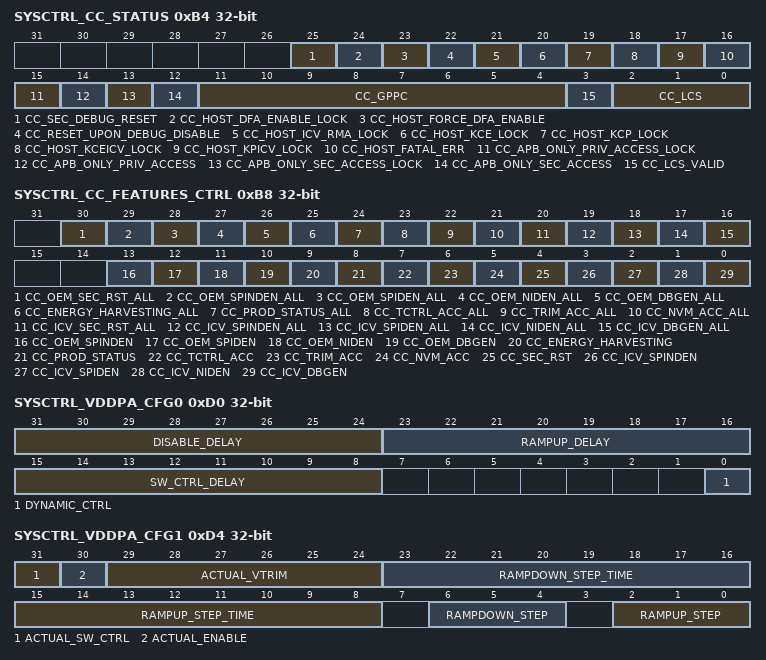
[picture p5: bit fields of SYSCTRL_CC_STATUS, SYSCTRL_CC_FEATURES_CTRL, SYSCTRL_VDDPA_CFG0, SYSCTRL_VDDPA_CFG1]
0xB4 SYSCTRL_CC_STATUS ro — CryptoCell Always On block various status fields
  [25] CC_SEC_DEBUG_RESET — Always On block secure debug reset status
    0=CC_SEC_DBG_RST_IDLE (The CC312 does not have the secure debug reset activated); 1=CC_SEV_DBG_RST_ACTIVATED (The CC312 has secure debug reset fired, can't fire again)
  [24] CC_HOST_DFA_ENABLE_LOCK — Always On block host AES DFA lock status
    0=CC_DFA_CFG_UNLOCKED (The CC312 AES DFA configuration register is unlocked); 1=CC_DFA_CFG_LOCKED (The CC312 AES DFA configuration register is locked)
  [23] CC_HOST_FORCE_DFA_ENABLE — Always On block host AES DFA status
    0=CC_DFA_DIS (The CC312 AES DFA counter measures are not enabled); 1=CC_DFA_EN (The CC312 AES DFA counter measures are enabled)
  [22] CC_RESET_UPON_DEBUG_DISABLE — Always On block HUK reset mechanism configuration status
    0=CC_RESET_UPON_DEBUG_EN (The CC312 HUK reset mechanism is enabled); 1=CC_RESET_UPON_DEBUG_DIS (The CC312 HUK reset mechanism is disabled)
  [21] CC_HOST_ICV_RMA_LOCK — Always On block host icv rma bit in NVM lock status
    0=CC_ICV_RMA_UNLOCKED (The CC312 icv_rma flag in NVM can be written); 1=CC_ICV_RMA_LOCKED (The CC312 icv_rma flag in NVM is locked, can't be written)
  [20] CC_HOST_KCE_LOCK — Always On block host OEM code encryption key lock status
    0=CC_KCE_UNLOCKED (The CC312 KCE is unlocked); 1=CC_KCE_LOCKED (The CC312 KCE is masked, locked by the SW)
  [19] CC_HOST_KCP_LOCK — Always On block host OEM provisioning key lock status
    0=CC_KCP_UNLOCKED (The CC312 KCP is unlocked); 1=CC_KCP_LOCKED (The CC312 KCP is masked, locked by the SW)
  [18] CC_HOST_KCEICV_LOCK — Always On block host ICV code encryption key lock status
    0=CC_KCEICV_UNLOCKED (The CC312 KCEICV is unlocked); 1=CC_KCEICV_LOCKED (The CC312 KCEICV is masked, locked by the SW)
  [17] CC_HOST_KPICV_LOCK — Always On block host ICV provisioning key lock status
    0=CC_KPICV_UNLOCKED (The CC312 KPICV is unlocked); 1=CC_KPICV_LOCKED (The CC312 KPICV is masked, locked by the SW)
  [16] CC_HOST_FATAL_ERR — Always On block host fatal error flag
    0=CC_HOST_NO_FATAL_ERROR (The CC312 does not have any fatal error); 1=CC_HOST_FATAL_ERROR (The CC312 reports a fatal error)
  [15] CC_APB_ONLY_PRIV_ACCESS_LOCK — Always On block APB filtering privileged access configuration lock
    0=CC_APB_PRIV_CFG_UNLOCK (The CC312 privileged access configuration field unlocked); 1=CC_APB_PRIV_CFG_LOCK (The CC312 privileged access configuration field locked)
  [14] CC_APB_ONLY_PRIV_ACCESS — Always On block APB filtering privileged access configuration
    0=CC_APB_NORMAL_ACCESS (The CC312 serve both privileged and normal access); 1=CC_APB_PRIV_ACCESS (The CC312 serve only privileged access)
  [13] CC_APB_ONLY_SEC_ACCESS_LOCK — Always On block APB filtering secure access configuration lock
    0=CC_APB_SEC_CFG_UNLOCK (The CC312 secure access configuration field is unlocked); 1=CC_APB_SEC_CFG_LOCKED (The CC312 secure access configuration field is locked)
  [12] CC_APB_ONLY_SEC_ACCESS — Always On block APB filtering secure access configuration
    0=CC_APB_NON_SEC_ACCESS (The CC312 allow both secure and non-secure access); 1=CC_APB_ONLY_SEC_ACCESS (The CC312 allow only secure access)
  [11:4] CC_GPPC — Always On block GPPC register
  [3] CC_LCS_VALID — Always On block life cycle state valid
    0=CC_LCS_IS_INVALID (The CC312 does not have LCS defined after reset); 1=CC_LCS_IS_VALID (The CC312 has LCS defined after reset)
  [2:0] CC_LCS — Always On block life cycle state
    0=CC_LCS_CM (The CC312 is in CM lifecycle state); 1=CC_LCS_DM (The CC312 is in DM lifecycle state); 5=CC_LCS_SECURE (The CC312 is in Secure lifecycle state); 7=CC_LCS_RMA (The CC312 is in RMA lifecycle state)
0xB8 SYSCTRL_CC_FEATURES_CTRL ro — CryptoCell always on block debug features control
  [30] CC_OEM_SEC_RST_ALL — Always On block OEM governed DCU_EN bits fault status allocated for enabling SEC_RST operation
    0=CC_OEM_SEC_RST_DCUEN_MATCH (The DCU_EN bits allocated for the feature are all equal); 1=CC_OEM_SEC_RST_DCUEN_MISMATCH (The DCU_EN bits allocated for the feature have mismatch)
  [29] CC_OEM_SPINDEN_ALL — Always On block OEM governed DCU_EN bits fault status allocated for enabling SPINDEN operation
    0=CC_OEM_SPINDEN_DCUEN_MATCH (The DCU_EN bits allocated for the feature are all equal); 1=CC_OEM_SPINDEN_DCUEN_MISMATCH (The DCU_EN bits allocated for the feature have mismatch)
  [28] CC_OEM_SPIDEN_ALL — Always On block OEM governed DCU_EN bits fault status allocated for enabling SPIDEN operation
    0=CC_OEM_SPIDEN_DCUEN_MATCH (The DCU_EN bits allocated for the feature are all equal); 1=CC_OEM_SPIDEN_DCUEN_MISMATCH (The DCU_EN bits allocated for the feature have mismatch)
  [27] CC_OEM_NIDEN_ALL — Always On block OEM governed DCU_EN bits fault status allocated for enabling NIDEN operation
    0=CC_OEM_NIDEN_DCUEN_MATCH (The DCU_EN bits allocated for the feature are all equal); 1=CC_OEM_NIDEN_DCUEN_MISMATCH (The DCU_EN bits allocated for the feature have mismatch)
  [26] CC_OEM_DBGEN_ALL — Always On block OEM governed DCU_EN bits fault status allocated for enabling DBGEN operation
    0=CC_OEM_DBGEN_DCUEN_MATCH (The DCU_EN bits allocated for the feature are all equal); 1=CC_OEM_DBGEN_DCUEN_MISMATCH (The DCU_EN bits allocated for the feature have mismatch)
  [25] CC_ENERGY_HARVESTING_ALL — Always On block DCU_EN bits fault status allocated for enabling ENERGY_HARVESTING operation
    0=CC_ENERGY_HARVESTING_DCUEN_MATCH (The DCU_EN bits allocated for the feature are all equal); 1=CC_ENERGY_HARVESTING_DCUEN_MISMATCH (The DCU_EN bits allocated for the feature have mismatch)
  [24] CC_PROD_STATUS_ALL — Always On block DCU_EN bits fault status allocated for enabling PROD_STATUS operation
    0=CC_PROD_STATUS_DCUEN_MATCH (The DCU_EN bits allocated for the feature are all equal); 1=CC_PROD_STATUS_DCUEN_MISMATCH (The DCU_EN bits allocated for the feature have mismatch)
  [23] CC_TCTRL_ACC_ALL — Always On block DCU_EN bits fault status allocated for enabling TCTRL_ACC operation
    0=CC_TCTRL_ACC_DCUEN_MATCH (The DCU_EN bits allocated for the feature are all equal); 1=CC_TCTRL_ACC_DCUEN_MISMATCH (The DCU_EN bits allocated for the feature have mismatch)
  [22] CC_TRIM_ACC_ALL — Always On block DCU_EN bits fault status allocated for enabling TRIM_ACC operation
    0=CC_TRIM_ACC_DCUEN_MATCH (The DCU_EN bits allocated for the feature are all equal); 1=CC_TRIM_ACC_DCUEN_MISMATCH (The DCU_EN bits allocated for the feature have mismatch)
  [21] CC_NVM_ACC_ALL — Always On block DCU_EN bits fault status allocated for enabling NVM_ACC operation
    0=CC_NVM_ACC_DCUEN_MATCH (The DCU_EN bits allocated for the feature are all equal); 1=CC_NVM_ACC_DCUEN_MISMATCH (The DCU_EN bits allocated for the feature have mismatch)
  [20] CC_ICV_SEC_RST_ALL — Always On block ICV governed DCU_EN bits fault status allocated for enabling SEC_RST operation
    0=CC_ICV_SEC_RST_DCUEN_MATCH (The DCU_EN bits allocated for the feature are all equal); 1=CC_ICV_SEC_RST_DCUEN_MISMATCH (The DCU_EN bits allocated for the feature have mismatch)
  [19] CC_ICV_SPINDEN_ALL — Always On block ICV governed DCU_EN bits fault status allocated for enabling SPINDEN operation
    0=CC_ICV_SPINDEN_DCUEN_MATCH (The DCU_EN bits allocated for the feature are all equal); 1=CC_ICV_SPINDEN_DCUEN_MISMATCH (The DCU_EN bits allocated for the feature have mismatch)
  [18] CC_ICV_SPIDEN_ALL — Always On block ICV governed DCU_EN bits fault status allocated for enabling SPIDEN operation
    0=CC_ICV_SPIDEN_DCUEN_MATCH (The DCU_EN bits allocated for the feature are all equal); 1=CC_ICV_SPIDEN_DCUEN_MISMATCH (The DCU_EN bits allocated for the feature have mismatch)
  [17] CC_ICV_NIDEN_ALL — Always On block ICV governed DCU_EN bits fault status allocated for enabling NIDEN operation
    0=CC_ICV_NIDEN_DCUEN_MATCH (The DCU_EN bits allocated for the feature are all equal); 1=CC_ICV_NIDEN_DCUEN_MISMATCH (The DCU_EN bits allocated for the feature have mismatch)
  [16] CC_ICV_DBGEN_ALL — Always On block ICV governed DCU_EN bits fault status allocated for enabling DBGEN operation
    0=CC_ICV_DBGEN_DCUEN_MATCH (The DCU_EN bits allocated for the feature are all equal); 1=CC_ICV_DBGEN_DCUEN_MISMATCH (The DCU_EN bits allocated for the feature have mismatch)
  [13] CC_OEM_SPINDEN — Always On block OEM SPINDEN status as the result of the equality check and production state confirmation
    0=CC_OEM_SPINDEN_INACTIVE (Secure non-invasive CM33 debug disabled by OEM); 1=CC_OEM_SPINDEN_ACTIVE (Secure non-invasive CM33 debug enabled by OEM, all bits set)
  [12] CC_OEM_SPIDEN — Always On block OEM SPIDEN status as the result of the equality check and production state confirmation
    0=CC_OEM_SPIDEN_INACTIVE (Secure invasive CM33 debug disabled by OEM); 1=CC_OEM_SPIDEN_ACTIVE (Secure invasive CM33 debug enabled by OEM, all bits set)
  [11] CC_OEM_NIDEN — Always On block OEM NIDEN status as the result of the equality check and production state confirmation
    0=CC_OEM_NIDEN_INACTIVE (Non-invasive CM33 debug disabled by OEM); 1=CC_OEM_NIDEN_ACTIVE (Non-invasive CM33 debug enabled by OEM, all bits set)
  [10] CC_OEM_DBGEN — Always On block OEM DBGEN status as the result of the equality check and production state confirmation
    0=CC_OEM_DBGEN_INACTIVE (CM33 debug disabled by OEM); 1=CC_OEM_DBGEN_ACTIVE (CM33 debug enabled by OEM, all bits set)
  [9] CC_ENERGY_HARVESTING — Always On block Energy Harvesting status as the result of equality check
    0=CC_ENERGY_HARVESTING_INACTIVE (Energy harvesting is inactive.); 1=CC_ENERGY_HARVESTING_ACTIVE (Energy harvesting is active, all bits set)
  [8] CC_PROD_STATUS — Always On block Production Status as the result of equality check
    0=CC_PROD_NOT_DONE (Production is not done.); 1=CC_PROD_DONE (Production screening done, all bits set)
  [7] CC_TCTRL_ACC — Always On block TCTRL_ACC status as the result of the equality check and production state confirmation
    0=CC_TCTRL_ACC_INACTIVE (Test_ctrl register access disabled); 1=CC_TCTRL_ACC_ACTIVE (Test_ctrl register access enabled, all bits set)
  [6] CC_TRIM_ACC — Always On block TRIM_ACC status as the result of the equality check and production state confirmation
    0=CC_TRIM_ACC_INACTIVE (MNVR and chip trim access disabled); 1=CC_TRIM_ACC_ACTIVE (MNVR and chip trim access enabled, all bits set)
  [5] CC_NVM_ACC — Always On block NVM_ACC status as the result of the equality check and production state confirmation
    0=CC_NVM_ACC_INACTIVE (NVM access limited); 1=CC_NVM_ACC_ACTIVE (NVM access available for ERASE and WRITE command, all bits set)
  [4] CC_SEC_RST — Always On block ICV or OEM SEC_RST status as the result of any bit being set.
    0=CC_SEC_RST_INACTIVE (None of the bits are set, the feature is deactivated by ICV or OEM); 1=CC_SEC_RST_ACTIVE (Some of the bits are set by ICV or OEM to activate the feature)
  [3] CC_ICV_SPINDEN — Always On block ICV SPINDEN status as the result of the equality check and production state confirmation
    0=CC_ICV_SPINDEN_INACTIVE (Secure non-invasive CM33 debug disabled by ICV); 1=CC_ICV_SPINDEN_ACTIVE (Secure non-invasive CM33 debug enabled by ICV, all bits set)
  [2] CC_ICV_SPIDEN — Always On block ICV SPIDEN status as the result of the equality check and production state confirmation
    0=CC_ICV_SPIDEN_INACTIVE (Secure invasive CM33 debug disabled by ICV); 1=CC_ICV_SPIDEN_ACTIVE (Secure invasive CM33 debug enabled by ICV, all bits set)
  [1] CC_ICV_NIDEN — Always On block ICV NIDEN status as the result of the equality check and production state confirmation
    0=CC_ICV_NIDEN_INACTIVE (Non-invasive CM33 debug disabled by ICV); 1=CC_ICV_NIDEN_ACTIVE (Non-invasive CM33 debug enabled by ICV, all bits set)
  [0] CC_ICV_DBGEN — Always On block ICV DBGEN status as the result of the equality check and production state confirmation
    0=CC_ICV_DBGEN_INACTIVE (CM33 debug disabled by ICV); 1=CC_ICV_DBGEN_ACTIVE (CM33 debug enabled by ICV, all bits set)
0xD0 SYSCTRL_VDDPA_CFG0 — VDDPA Dynamic Control Configuration 0
  [31:24] DISABLE_DELAY — VDDPA disable delay after ramp down (in system clock cycles)
    0=1 system clock cycle delay; 255=256 system clock cycles delay
  [23:16] RAMPUP_DELAY — VDDPA ramp up delay after regulator enabling (in system clock cycles)
    values as DISABLE_DELAY
  [15:8] SW_CTRL_DELAY — VDDPA SW_CTRL delay after regulator enabling (in system clock cycles)
    values as DISABLE_DELAY
  [0] DYNAMIC_CTRL — Dynamic VDDPA control (VDDPA is enabled when RF is in TX mode, disabled otherwise)
    0=DYNAMIC_CTRL_DISABLE (Disable dynamic VDDPA control); 1=DYNAMIC_CTRL_ENABLE (Enable dynamic VDDPA control)
0xD4 SYSCTRL_VDDPA_CFG1 — VDDPA Dynamic Control Configuration 1
  [31] ACTUAL_SW_CTRL ro — VDDPA actual SW_CTRL status
  [30] ACTUAL_ENABLE ro — VDDPA actual enable status
  [29:24] ACTUAL_VTRIM ro — VDDPA actual voltage trimming status
  [23:16] RAMPDOWN_STEP_TIME — VDDPA ramp down step duration (in system clock cycles)
    0=1 system clock cycle duration; 255=256 system clock cycles duration
  [15:8] RAMPUP_STEP_TIME — VDDPA ramp up step duration (in system clock cycles)
    values as RAMPDOWN_STEP_TIME
  [6:4] RAMPDOWN_STEP — Amount of VDDPA ramp down step(s)
    0=RAMPDOWN_1_STEP (1 ramp up voltage step); 1=RAMPDOWN_2_STEP (2 ramp up voltage steps); 2=RAMPDOWN_4_STEP (4 ramp up voltage steps); 3=RAMPDOWN_8_STEP (8 ramp up voltage steps); 4=RAMPDOWN_16_STEP (16 ramp up voltage steps); 5=RAMPDOWN_32_STEP (32 ramp up voltage steps); 6=RAMPDOWN_64_STEP (64 ramp up voltage steps)
  [2:0] RAMPUP_STEP — Amount of VDDPA ramp up step(s)
    0=RAMPUP_1_STEP (1 ramp down voltage step); 1=RAMPUP_2_STEP (2 ramp down voltage steps); 2=RAMPUP_4_STEP (4 ramp down voltage steps); 3=RAMPUP_8_STEP (8 ramp down voltage steps); 4=RAMPUP_16_STEP (16 ramp down voltage steps); 5=RAMPUP_32_STEP (32 ramp down voltage steps); 7=RAMPUP_64_STEP (64 ramp down voltage steps)
0x20034 SYSCTRL_WAKEUP_PAD_NS access not given reset not defined — WAKEUP Pad Value
0x2007C SYSCTRL_CNT_CTRL_NS access not given reset not defined — Activity Counters Control
0x20080 SYSCTRL_SYSCLK_CNT_NS access not given reset not defined — System Clock Counter Value
0x20084 SYSCTRL_CM33_CNT_NS access not given reset not defined — CM33 Activity Counter Value
0x20088 SYSCTRL_CBUS_CNT_NS access not given reset not defined — CBus Activity Counter Value
0x2008C SYSCTRL_FLASH_READ_CNT_NS access not given reset not defined — Flash Read Access Counter Value
